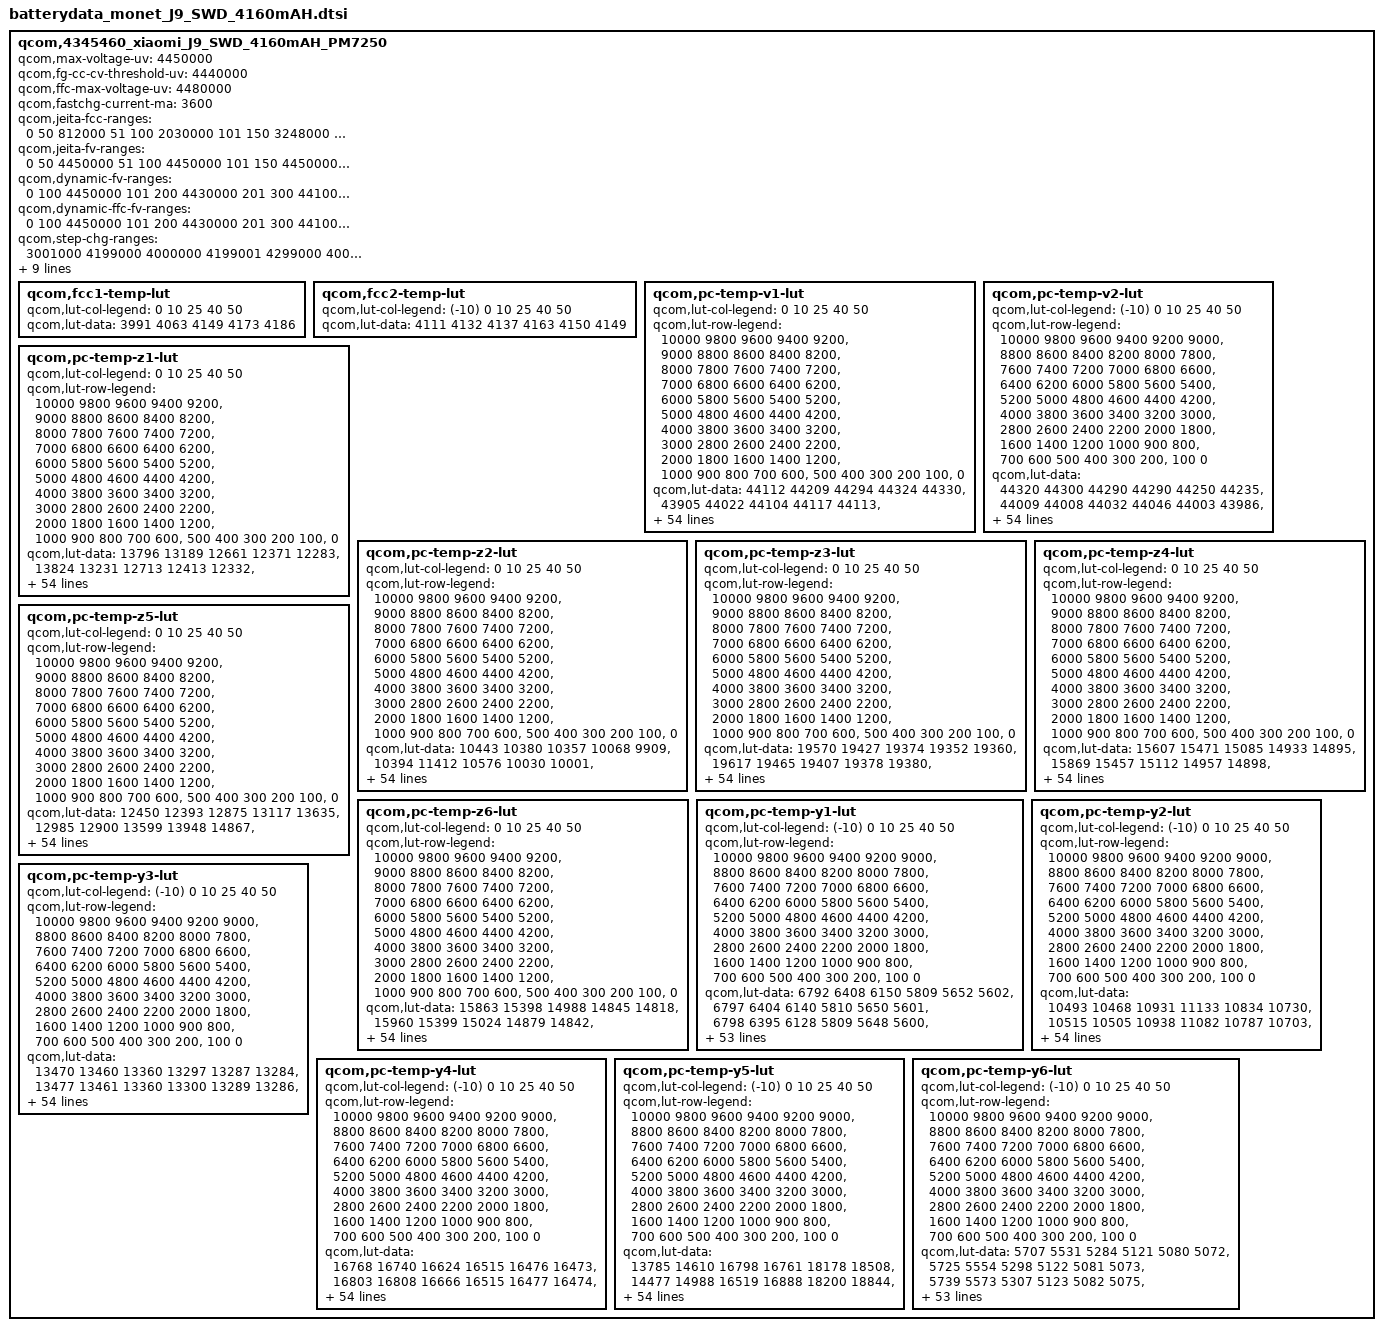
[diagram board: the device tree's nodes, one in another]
qcom,4345460_xiaomi_J9_SWD_4160mAH_PM7250 {
    /* 4345460_xiaomi_J9_SWD_4160mAH_PM7250_averaged_MasterSlave_Dec11th2019 */
    qcom,max-voltage-uv = <4450000>;
    qcom,fg-cc-cv-threshold-uv = <4440000>;
    qcom,ffc-max-voltage-uv = <4480000>;
    qcom,fastchg-current-ma = <3600>;
    qcom,jeita-fcc-ranges = <0  50  812000
			     51  100  2030000
			     101 150  3248000
			     151 450  3600000
			     451 580  2030000>;
    qcom,jeita-fv-ranges = <0   50  4450000
			    51  100  4450000
			    101 150  4450000
			    151 450  4480000
			    451 580  4100000>;
    qcom,dynamic-fv-ranges = <0    100  4450000
			    101  200  4430000
			    201  300  4410000
			    301  400  4390000
			    401  500  4370000>;
    qcom,dynamic-ffc-fv-ranges = <0    100  4450000
			    101  200  4430000
			    201  300  4410000
			    301  400  4390000
			    401  500  4370000>;
    qcom,step-chg-ranges = <3001000  4199000  4000000
			    4199001  4299000  4000000
			    4299001  4399000  4000000
                            4399001  4450000  4000000
                            4450001  4480000  3248000>;
    qcom,fg-cc-cv-threshold-mv = <4440>;
    qcom,nom-batt-capacity-mah = <4160>;
    qcom,batt-id-kohm = <330>;
    qcom,battery-beta = <4250>;
    qcom,battery-therm-kohm = <100>;
    qcom,cutoff-current-ua = <700000>;
    qcom,battery-type = "J9_SWD_4160mAH";
    qcom,qg-batt-profile-ver = <100>;
    mi,qc3p5-ffc-battery;

	qcom,fcc1-temp-lut {
		qcom,lut-col-legend = <0 10 25 40 50>;
		qcom,lut-data = <3991 4063 4149 4173 4186>;
	};

	qcom,fcc2-temp-lut {
		qcom,lut-col-legend = <(-10) 0 10 25 40 50>;
		qcom,lut-data = <4111 4132 4137 4163 4150 4149>;
	};

	qcom,pc-temp-v1-lut {
		qcom,lut-col-legend = <0 10 25 40 50>;
		qcom,lut-row-legend = <10000 9800 9600 9400 9200>,
			<9000 8800 8600 8400 8200>,
			<8000 7800 7600 7400 7200>,
			<7000 6800 6600 6400 6200>,
			<6000 5800 5600 5400 5200>,
			<5000 4800 4600 4400 4200>,
			<4000 3800 3600 3400 3200>,
			<3000 2800 2600 2400 2200>,
			<2000 1800 1600 1400 1200>,
			<1000 900 800 700 600>,
			<500 400 300 200 100>,
			<0>;
		qcom,lut-data = <44112 44209 44294 44324 44330>,
			<43905 44022 44104 44117 44113>,
			<43690 43821 43899 43912 43909>,
			<43468 43605 43692 43705 43704>,
			<43238 43377 43479 43496 43497>,
			<43000 43143 43255 43280 43284>,
			<42761 42903 43017 43049 43057>,
			<42520 42662 42772 42807 42816>,
			<42279 42417 42527 42565 42574>,
			<42042 42174 42281 42323 42333>,
			<41810 41937 42039 42083 42092>,
			<41583 41703 41799 41842 41852>,
			<41361 41475 41563 41602 41614>,
			<41146 41250 41333 41368 41380>,
			<40936 41034 41110 41143 41152>,
			<40733 40830 40895 40925 40929>,
			<40535 40635 40688 40715 40717>,
			<40339 40442 40487 40512 40512>,
			<40147 40256 40298 40318 40317>,
			<39965 40068 40121 40137 40138>,
			<39803 39860 39927 39948 39953>,
			<39635 39629 39675 39712 39723>,
			<39415 39402 39405 39453 39462>,
			<39137 39172 39202 39246 39251>,
			<38926 38970 39040 39081 39088>,
			<38810 38846 38907 38938 38946>,
			<38724 38759 38798 38811 38814>,
			<38651 38680 38702 38698 38694>,
			<38590 38598 38606 38593 38584>,
			<38534 38520 38512 38493 38485>,
			<38476 38448 38426 38404 38395>,
			<38418 38378 38352 38326 38316>,
			<38367 38317 38284 38254 38243>,
			<38320 38264 38223 38187 38172>,
			<38278 38218 38170 38124 38103>,
			<38238 38175 38119 38062 38033>,
			<38202 38139 38070 38003 37966>,
			<38157 38097 38021 37943 37895>,
			<38087 38031 37951 37866 37809>,
			<37994 37935 37854 37765 37700>,
			<37886 37826 37742 37651 37578>,
			<37752 37696 37617 37529 37452>,
			<37599 37548 37474 37393 37315>,
			<37421 37376 37306 37227 37143>,
			<37305 37227 37166 37094 37021>,
			<37212 37137 37085 37021 36958>,
			<37179 37111 37061 36996 36933>,
			<37148 37091 37045 36977 36918>,
			<37114 37073 37015 36952 36884>,
			<37023 36978 36904 36833 36728>,
			<36703 36679 36548 36471 36366>,
			<36214 36208 36065 35997 35891>,
			<35588 35602 35436 35383 35275>,
			<34725 34767 34568 34545 34432>,
			<33326 33440 33177 33221 33097>,
			<30000 30000 30000 30000 30000>;
	};

	qcom,pc-temp-v2-lut {
		qcom,lut-col-legend = <(-10) 0 10 25 40 50>;
		qcom,lut-row-legend = <10000 9800 9600 9400 9200 9000>,
			<8800 8600 8400 8200 8000 7800>,
			<7600 7400 7200 7000 6800 6600>,
			<6400 6200 6000 5800 5600 5400>,
			<5200 5000 4800 4600 4400 4200>,
			<4000 3800 3600 3400 3200 3000>,
			<2800 2600 2400 2200 2000 1800>,
			<1600 1400 1200 1000 900 800>,
			<700 600 500 400 300 200>,
			<100 0>;
		qcom,lut-data = <44320 44300 44290 44290 44250 44235>,
			<44009 44008 44032 44046 44003 43986>,
			<43725 43737 43784 43809 43766 43747>,
			<43471 43492 43551 43583 43538 43519>,
			<43249 43274 43334 43368 43322 43304>,
			<43027 43051 43112 43146 43101 43085>,
			<42788 42808 42872 42909 42866 42851>,
			<42543 42555 42625 42665 42624 42610>,
			<42296 42303 42379 42419 42382 42369>,
			<42046 42052 42131 42173 42138 42125>,
			<41798 41803 41885 41928 41896 41883>,
			<41549 41554 41644 41687 41657 41644>,
			<41302 41309 41406 41449 41422 41409>,
			<41087 41097 41174 41216 41191 41179>,
			<40916 40917 40949 40988 40965 40954>,
			<40726 40734 40733 40767 40747 40736>,
			<40427 40517 40533 40556 40538 40525>,
			<40044 40271 40339 40352 40336 40322>,
			<39753 40022 40130 40156 40144 40130>,
			<39554 39763 39905 39973 39965 39954>,
			<39374 39513 39673 39772 39772 39765>,
			<39179 39278 39432 39514 39528 39523>,
			<38984 39053 39191 39242 39265 39263>,
			<38796 38854 38988 39033 39054 39055>,
			<38606 38678 38816 38862 38879 38883>,
			<38441 38515 38664 38714 38728 38733>,
			<38325 38344 38529 38585 38600 38602>,
			<38233 38181 38408 38471 38488 38486>,
			<38157 38083 38296 38365 38384 38382>,
			<38092 38027 38188 38266 38287 38285>,
			<38033 37983 38090 38176 38199 38197>,
			<37972 37941 38001 38093 38122 38118>,
			<37914 37902 37922 38016 38050 38043>,
			<37855 37860 37861 37944 37975 37963>,
			<37796 37815 37818 37878 37898 37878>,
			<37734 37768 37777 37809 37813 37785>,
			<37669 37714 37735 37734 37712 37677>,
			<37599 37654 37690 37654 37601 37558>,
			<37522 37582 37629 37569 37502 37454>,
			<37434 37493 37543 37482 37416 37365>,
			<37339 37390 37436 37384 37324 37271>,
			<37244 37269 37308 37267 37210 37155>,
			<37150 37132 37161 37140 37085 37029>,
			<37060 36999 37018 37006 36961 36903>,
			<36976 36883 36897 36912 36872 36820>,
			<36891 36795 36820 36867 36836 36783>,
			<36845 36753 36785 36849 36825 36772>,
			<36797 36706 36742 36825 36806 36751>,
			<36740 36630 36669 36765 36754 36687>,
			<36642 36494 36522 36557 36549 36434>,
			<36422 36225 36204 36114 36123 35991>,
			<35991 35754 35711 35534 35567 35428>,
			<35350 35071 35042 34776 34849 34690>,
			<34456 34095 34133 33702 33878 33709>,
			<32973 32497 32635 32152 32265 31950>,
			<29640 27567 28928 26774 27941 27767>;
	};

	qcom,pc-temp-z1-lut {
		qcom,lut-col-legend = <0 10 25 40 50>;
		qcom,lut-row-legend = <10000 9800 9600 9400 9200>,
			<9000 8800 8600 8400 8200>,
			<8000 7800 7600 7400 7200>,
			<7000 6800 6600 6400 6200>,
			<6000 5800 5600 5400 5200>,
			<5000 4800 4600 4400 4200>,
			<4000 3800 3600 3400 3200>,
			<3000 2800 2600 2400 2200>,
			<2000 1800 1600 1400 1200>,
			<1000 900 800 700 600>,
			<500 400 300 200 100>,
			<0>;
		qcom,lut-data = <13796 13189 12661 12371 12283>,
			<13824 13231 12713 12413 12332>,
			<13855 13242 12730 12429 12347>,
			<13873 13242 12729 12433 12353>,
			<13862 13237 12718 12431 12353>,
			<13838 13227 12709 12428 12351>,
			<13822 13210 12702 12424 12349>,
			<13802 13197 12692 12419 12347>,
			<13781 13188 12681 12415 12346>,
			<13770 13178 12670 12411 12346>,
			<13760 13164 12665 12410 12347>,
			<13756 13144 12664 12410 12347>,
			<13748 13134 12664 12410 12348>,
			<13732 13131 12663 12411 12348>,
			<13720 13129 12661 12411 12349>,
			<13699 13126 12661 12411 12350>,
			<13681 13124 12661 12412 12351>,
			<13668 13124 12662 12414 12353>,
			<13656 13125 12663 12416 12355>,
			<13653 13127 12665 12419 12358>,
			<13662 13128 12668 12421 12360>,
			<13673 13131 12670 12421 12361>,
			<13677 13134 12673 12420 12361>,
			<13678 13137 12675 12421 12362>,
			<13678 13140 12678 12424 12364>,
			<13680 13144 12681 12428 12367>,
			<13685 13152 12687 12432 12371>,
			<13686 13158 12693 12436 12375>,
			<13681 13159 12699 12441 12379>,
			<13678 13159 12703 12446 12383>,
			<13683 13162 12707 12451 12387>,
			<13692 13172 12711 12456 12392>,
			<13700 13180 12716 12461 12397>,
			<13709 13186 12722 12467 12402>,
			<13718 13192 12731 12474 12407>,
			<13722 13196 12740 12480 12412>,
			<13726 13197 12746 12485 12417>,
			<13733 13199 12753 12490 12422>,
			<13759 13206 12759 12495 12427>,
			<13794 13222 12765 12500 12431>,
			<13813 13239 12772 12505 12436>,
			<13824 13259 12780 12511 12440>,
			<13829 13275 12790 12516 12443>,
			<13839 13283 12802 12521 12446>,
			<13864 13287 12817 12529 12452>,
			<13892 13296 12828 12535 12454>,
			<13846 13291 12824 12535 12455>,
			<13835 13288 12829 12537 12456>,
			<13864 13297 12836 12542 12461>,
			<13878 13304 12844 12549 12466>,
			<13894 13308 12856 12558 12473>,
			<13890 13322 12864 12563 12482>,
			<13918 13328 12875 12577 12493>,
			<13942 13356 12892 12590 12506>,
			<13942 13356 12892 12590 12506>,
			<13942 13356 12892 12590 12506>;
	};

	qcom,pc-temp-z2-lut {
		qcom,lut-col-legend = <0 10 25 40 50>;
		qcom,lut-row-legend = <10000 9800 9600 9400 9200>,
			<9000 8800 8600 8400 8200>,
			<8000 7800 7600 7400 7200>,
			<7000 6800 6600 6400 6200>,
			<6000 5800 5600 5400 5200>,
			<5000 4800 4600 4400 4200>,
			<4000 3800 3600 3400 3200>,
			<3000 2800 2600 2400 2200>,
			<2000 1800 1600 1400 1200>,
			<1000 900 800 700 600>,
			<500 400 300 200 100>,
			<0>;
		qcom,lut-data = <10443 10380 10357 10068 9909>,
			<10394 11412 10576 10030 10001>,
			<10345 11548 11046 10115 10007>,
			<10304 10931 11145 10154 10005>,
			<10266 10383 10979 10165 9988>,
			<10234 10328 10766 10170 9966>,
			<10214 10301 10543 10161 9974>,
			<10200 10281 10317 10137 10013>,
			<10190 10262 10235 10132 10034>,
			<10187 10250 10202 10370 9991>,
			<10185 10245 10190 10624 9935>,
			<10184 10242 10194 10522 9921>,
			<10191 10242 10203 10200 9917>,
			<10204 10254 10236 10067 9912>,
			<10217 10279 10397 10056 9902>,
			<10230 10392 10539 10052 9897>,
			<10247 10613 10584 10209 9907>,
			<10278 10693 10613 10614 9927>,
			<10317 10543 10594 10734 9942>,
			<10330 10371 10411 10374 9951>,
			<10328 10341 10278 10041 9963>,
			<10325 10341 10332 10120 10049>,
			<10320 10343 10407 10296 10224>,
			<10313 10335 10407 10330 10275>,
			<10309 10322 10339 10197 10178>,
			<10309 10324 10297 10089 10087>,
			<10311 10342 10323 10181 10128>,
			<10315 10362 10369 10364 10231>,
			<10325 10379 10396 10401 10255>,
			<10337 10394 10416 10305 10146>,
			<10346 10395 10424 10201 10019>,
			<10355 10383 10390 10140 9943>,
			<10361 10372 10339 10094 9883>,
			<10364 10370 10330 10085 9872>,
			<10367 10372 10334 10094 9896>,
			<10372 10376 10340 10109 9932>,
			<10380 10382 10358 10148 9979>,
			<10392 10392 10390 10212 10038>,
			<10409 10408 10424 10265 10086>,
			<10431 10434 10469 10314 10134>,
			<10451 10456 10496 10344 10159>,
			<10467 10471 10504 10347 10137>,
			<10499 10489 10510 10344 10108>,
			<10571 10518 10510 10343 10222>,
			<10423 10722 10560 10283 10195>,
			<10307 10787 10558 10208 10088>,
			<10241 10764 10558 10209 10083>,
			<10200 10775 10527 10193 10094>,
			<10172 10868 10553 10245 10167>,
			<10181 10828 10570 10304 10135>,
			<10155 10829 10523 10121 9964>,
			<10027 10692 10398 10025 9906>,
			<9946 10665 10383 9983 9858>,
			<9781 10461 10319 9961 9836>,
			<9781 10461 10319 9961 9836>,
			<9781 10461 10319 9961 9836>;
	};

	qcom,pc-temp-z3-lut {
		qcom,lut-col-legend = <0 10 25 40 50>;
		qcom,lut-row-legend = <10000 9800 9600 9400 9200>,
			<9000 8800 8600 8400 8200>,
			<8000 7800 7600 7400 7200>,
			<7000 6800 6600 6400 6200>,
			<6000 5800 5600 5400 5200>,
			<5000 4800 4600 4400 4200>,
			<4000 3800 3600 3400 3200>,
			<3000 2800 2600 2400 2200>,
			<2000 1800 1600 1400 1200>,
			<1000 900 800 700 600>,
			<500 400 300 200 100>,
			<0>;
		qcom,lut-data = <19570 19427 19374 19352 19360>,
			<19617 19465 19407 19378 19380>,
			<19717 19493 19442 19406 19397>,
			<19779 19559 19468 19426 19409>,
			<19798 19616 19497 19437 19416>,
			<19810 19627 19515 19446 19423>,
			<19816 19633 19517 19453 19431>,
			<19817 19636 19518 19460 19440>,
			<19818 19639 19517 19466 19443>,
			<19819 19641 19515 19477 19442>,
			<19818 19637 19512 19486 19439>,
			<19816 19627 19506 19479 19436>,
			<19809 19619 19499 19459 19432>,
			<19801 19608 19497 19445 19428>,
			<19798 19600 19503 19436 19425>,
			<19797 19607 19507 19430 19421>,
			<19795 19626 19499 19430 19416>,
			<19781 19632 19489 19434 19410>,
			<19758 19606 19479 19433 19404>,
			<19750 19579 19462 19418 19396>,
			<19757 19583 19451 19405 19391>,
			<19769 19609 19467 19410 19394>,
			<19787 19624 19491 19421 19402>,
			<19813 19619 19489 19421 19404>,
			<19827 19607 19460 19397 19390>,
			<19818 19595 19440 19376 19377>,
			<19800 19576 19438 19399 19400>,
			<19785 19566 19437 19446 19454>,
			<19770 19572 19445 19463 19471>,
			<19760 19586 19482 19467 19464>,
			<19759 19598 19505 19469 19453>,
			<19760 19610 19504 19463 19441>,
			<19760 19617 19503 19450 19427>,
			<19757 19614 19500 19439 19415>,
			<19754 19609 19489 19428 19405>,
			<19751 19604 19478 19419 19396>,
			<19748 19599 19471 19411 19389>,
			<19745 19594 19465 19405 19383>,
			<19738 19589 19461 19400 19382>,
			<19729 19582 19458 19397 19381>,
			<19719 19576 19456 19396 19381>,
			<19708 19571 19455 19398 19384>,
			<19691 19564 19454 19402 19392>,
			<19661 19546 19448 19405 19404>,
			<19409 19497 19428 19399 19402>,
			<19338 19473 19409 19371 19372>,
			<19322 19467 19410 19369 19366>,
			<19316 19444 19396 19368 19352>,
			<19312 19335 19393 19351 19345>,
			<19315 19440 19368 19354 19365>,
			<19323 19340 19388 19395 19388>,
			<19324 19321 19380 19396 19389>,
			<19326 19306 19380 19398 19388>,
			<19333 19309 19377 19384 19385>,
			<19333 19309 19377 19384 19385>,
			<19333 19309 19377 19384 19385>;
	};

	qcom,pc-temp-z4-lut {
		qcom,lut-col-legend = <0 10 25 40 50>;
		qcom,lut-row-legend = <10000 9800 9600 9400 9200>,
			<9000 8800 8600 8400 8200>,
			<8000 7800 7600 7400 7200>,
			<7000 6800 6600 6400 6200>,
			<6000 5800 5600 5400 5200>,
			<5000 4800 4600 4400 4200>,
			<4000 3800 3600 3400 3200>,
			<3000 2800 2600 2400 2200>,
			<2000 1800 1600 1400 1200>,
			<1000 900 800 700 600>,
			<500 400 300 200 100>,
			<0>;
		qcom,lut-data = <15607 15471 15085 14933 14895>,
			<15869 15457 15112 14957 14898>,
			<15744 15417 15092 14949 14902>,
			<15595 15323 15060 14938 14904>,
			<15482 15228 15001 14914 14889>,
			<15376 15157 14951 14884 14865>,
			<15286 15094 14924 14860 14844>,
			<15211 15039 14903 14839 14823>,
			<15147 14989 14881 14814 14804>,
			<15091 14948 14857 14773 14787>,
			<15043 14917 14832 14740 14773>,
			<15005 14891 14812 14737 14762>,
			<14974 14868 14793 14746 14752>,
			<14947 14849 14772 14748 14744>,
			<14919 14828 14743 14744 14739>,
			<14887 14791 14724 14739 14734>,
			<14869 14744 14720 14725 14730>,
			<14869 14730 14717 14700 14725>,
			<14871 14754 14715 14690 14720>,
			<14870 14783 14723 14695 14714>,
			<14850 14799 14739 14708 14710>,
			<14828 14814 14775 14740 14731>,
			<14845 14834 14825 14794 14789>,
			<14916 14897 14869 14837 14827>,
			<14964 14962 14917 14877 14850>,
			<14968 14971 14939 14900 14863>,
			<14969 14966 14932 14868 14831>,
			<14966 14958 14916 14800 14756>,
			<14951 14936 14890 14764 14726>,
			<14931 14901 14838 14745 14722>,
			<14912 14872 14799 14733 14718>,
			<14890 14845 14781 14727 14715>,
			<14873 14827 14770 14723 14713>,
			<14860 14820 14766 14722 14711>,
			<14849 14816 14765 14723 14710>,
			<14840 14813 14764 14724 14709>,
			<14833 14811 14765 14725 14710>,
			<14827 14809 14767 14726 14711>,
			<14824 14811 14771 14731 14715>,
			<14822 14814 14781 14747 14731>,
			<14817 14814 14787 14757 14744>,
			<14805 14800 14778 14751 14737>,
			<14792 14783 14765 14741 14726>,
			<14779 14773 14760 14738 14723>,
			<14906 14735 14736 14723 14707>,
			<14949 14714 14710 14713 14694>,
			<14957 14708 14693 14700 14688>,
			<14956 14715 14684 14678 14677>,
			<14956 14829 14670 14670 14654>,
			<14952 14710 14708 14670 14654>,
			<14960 14846 14719 14680 14681>,
			<14973 14875 14733 14685 14687>,
			<14976 14893 14733 14687 14692>,
			<14986 14893 14739 14702 14695>,
			<14986 14893 14739 14702 14695>,
			<14986 14893 14739 14702 14695>;
	};

	qcom,pc-temp-z5-lut {
		qcom,lut-col-legend = <0 10 25 40 50>;
		qcom,lut-row-legend = <10000 9800 9600 9400 9200>,
			<9000 8800 8600 8400 8200>,
			<8000 7800 7600 7400 7200>,
			<7000 6800 6600 6400 6200>,
			<6000 5800 5600 5400 5200>,
			<5000 4800 4600 4400 4200>,
			<4000 3800 3600 3400 3200>,
			<3000 2800 2600 2400 2200>,
			<2000 1800 1600 1400 1200>,
			<1000 900 800 700 600>,
			<500 400 300 200 100>,
			<0>;
		qcom,lut-data = <12450 12393 12875 13117 13635>,
			<12985 12900 13599 13948 14867>,
			<13955 13314 14390 15298 16040>,
			<14657 14357 14938 16273 16865>,
			<14982 15343 15638 16790 17307>,
			<15219 15679 16272 17258 17703>,
			<15499 15944 16650 17849 18431>,
			<15852 16308 16956 18524 19591>,
			<16258 16871 17250 19412 20334>,
			<16755 17397 17538 22023 20623>,
			<17351 17747 17888 24454 20878>,
			<17935 18064 18328 24135 21269>,
			<18468 18463 18904 22354 21975>,
			<19068 18944 19990 21463 22657>,
			<19999 19635 22459 21280 23333>,
			<21620 21784 24337 21192 23907>,
			<22717 25485 24769 22924 24293>,
			<22667 26782 24942 27307 24713>,
			<22422 24457 24746 28838 24823>,
			<22467 21915 22784 26358 25139>,
			<23921 23892 21659 24141 25521>,
			<26611 32120 26045 25165 25881>,
			<31469 36793 32077 26917 26494>,
			<40093 34011 31575 26672 26221>,
			<44573 29025 23907 20505 20783>,
			<40940 25749 18315 15478 15768>,
			<34448 22029 17078 16433 18255>,
			<30508 20195 16390 19008 24598>,
			<27788 20528 16823 21375 27232>,
			<26335 21416 19596 23883 27828>,
			<26665 22836 22531 25579 28089>,
			<27806 25900 24822 25950 27403>,
			<28918 28722 26766 25986 25889>,
			<29957 30392 27699 25969 25244>,
			<30954 31685 28279 26126 25065>,
			<31772 32014 28505 26173 24913>,
			<32539 31914 28342 25879 24732>,
			<33036 31718 27952 25366 24515>,
			<33282 31211 27289 24610 24038>,
			<33408 30199 25840 23239 22660>,
			<33166 29501 24734 22062 21696>,
			<32056 29219 24361 21359 21799>,
			<31028 28707 23999 20966 22166>,
			<29737 26530 22822 21679 25805>,
			<16214 27534 22782 21661 26446>,
			<12816 26290 22098 17822 18932>,
			<12425 24627 23521 18166 18362>,
			<12290 21527 21650 20152 17562>,
			<12198 13348 23410 19300 20562>,
			<12297 20769 16805 18949 30629>,
			<12396 13067 16821 21611 22270>,
			<12228 12417 15367 20154 20120>,
			<12131 11973 15099 19052 18296>,
			<12027 11913 14514 15661 16073>,
			<12027 11913 14514 15661 16073>,
			<12027 11913 14514 15661 16073>;
	};

	qcom,pc-temp-z6-lut {
		qcom,lut-col-legend = <0 10 25 40 50>;
		qcom,lut-row-legend = <10000 9800 9600 9400 9200>,
			<9000 8800 8600 8400 8200>,
			<8000 7800 7600 7400 7200>,
			<7000 6800 6600 6400 6200>,
			<6000 5800 5600 5400 5200>,
			<5000 4800 4600 4400 4200>,
			<4000 3800 3600 3400 3200>,
			<3000 2800 2600 2400 2200>,
			<2000 1800 1600 1400 1200>,
			<1000 900 800 700 600>,
			<500 400 300 200 100>,
			<0>;
		qcom,lut-data = <15863 15398 14988 14845 14818>,
			<15960 15399 15024 14879 14842>,
			<15915 15387 15034 14892 14856>,
			<15854 15360 15030 14895 14860>,
			<15794 15335 15017 14891 14857>,
			<15728 15305 15003 14884 14852>,
			<15671 15266 14991 14878 14848>,
			<15620 15233 14978 14871 14844>,
			<15576 15205 14965 14864 14839>,
			<15539 15181 14952 14855 14832>,
			<15507 15158 14938 14846 14824>,
			<15479 15137 14925 14838 14817>,
			<15454 15118 14913 14831 14811>,
			<15431 15102 14903 14824 14805>,
			<15410 15087 14895 14818 14801>,
			<15391 15075 14888 14812 14796>,
			<15374 15065 14881 14805 14792>,
			<15358 15060 14875 14799 14786>,
			<15345 15057 14870 14794 14781>,
			<15341 15056 14866 14788 14774>,
			<15341 15060 14865 14785 14770>,
			<15341 15081 14887 14800 14781>,
			<15355 15103 14924 14832 14812>,
			<15403 15128 14939 14846 14826>,
			<15431 15150 14946 14851 14829>,
			<15429 15150 14948 14853 14830>,
			<15424 15142 14944 14851 14828>,
			<15416 15133 14937 14848 14826>,
			<15403 15127 14933 14844 14823>,
			<15391 15122 14930 14840 14818>,
			<15383 15118 14927 14835 14812>,
			<15377 15114 14922 14829 14806>,
			<15372 15111 14917 14822 14798>,
			<15367 15108 14913 14817 14791>,
			<15364 15106 14908 14813 14786>,
			<15364 15105 14905 14809 14781>,
			<15365 15104 14903 14805 14778>,
			<15366 15104 14901 14802 14775>,
			<15370 15106 14902 14803 14775>,
			<15376 15110 14907 14808 14782>,
			<15379 15111 14910 14812 14787>,
			<15380 15108 14908 14811 14787>,
			<15380 15104 14904 14810 14786>,
			<15378 15100 14901 14811 14792>,
			<15329 15073 14886 14803 14785>,
			<15310 15056 14868 14785 14764>,
			<15306 15050 14861 14778 14759>,
			<15305 15044 14851 14769 14747>,
			<15310 15040 14845 14756 14733>,
			<15319 15050 14851 14759 14744>,
			<15333 15062 14871 14787 14771>,
			<15347 15070 14876 14793 14778>,
			<15361 15078 14881 14798 14783>,
			<15386 15091 14888 14801 14787>,
			<15386 15091 14888 14801 14787>,
			<15386 15091 14888 14801 14787>;
	};

	qcom,pc-temp-y1-lut {
		qcom,lut-col-legend = <(-10) 0 10 25 40 50>;
		qcom,lut-row-legend = <10000 9800 9600 9400 9200 9000>,
			<8800 8600 8400 8200 8000 7800>,
			<7600 7400 7200 7000 6800 6600>,
			<6400 6200 6000 5800 5600 5400>,
			<5200 5000 4800 4600 4400 4200>,
			<4000 3800 3600 3400 3200 3000>,
			<2800 2600 2400 2200 2000 1800>,
			<1600 1400 1200 1000 900 800>,
			<700 600 500 400 300 200>,
			<100 0>;
		qcom,lut-data = <6792 6408 6150 5809 5652 5602>,
			<6797 6404 6140 5810 5650 5601>,
			<6798 6395 6128 5809 5648 5600>,
			<6798 6385 6117 5808 5646 5599>,
			<6796 6376 6107 5806 5645 5598>,
			<6793 6372 6102 5804 5643 5597>,
			<6786 6372 6100 5799 5641 5596>,
			<6777 6372 6100 5795 5640 5596>,
			<6776 6370 6100 5794 5638 5595>,
			<6785 6363 6095 5795 5637 5593>,
			<6792 6359 6091 5795 5636 5591>,
			<6792 6363 6090 5794 5635 5591>,
			<6792 6372 6089 5792 5634 5591>,
			<6792 6374 6088 5790 5634 5591>,
			<6793 6374 6087 5788 5634 5590>,
			<6796 6374 6086 5788 5634 5590>,
			<6805 6378 6088 5789 5634 5590>,
			<6820 6385 6092 5792 5635 5591>,
			<6826 6388 6092 5792 5636 5592>,
			<6826 6388 6091 5791 5636 5592>,
			<6826 6388 6090 5791 5637 5593>,
			<6828 6387 6090 5793 5638 5594>,
			<6834 6385 6091 5797 5640 5597>,
			<6835 6384 6093 5801 5642 5599>,
			<6817 6385 6100 5806 5645 5601>,
			<6800 6386 6107 5809 5648 5602>,
			<6801 6388 6104 5812 5650 5604>,
			<6810 6392 6099 5813 5652 5606>,
			<6812 6392 6098 5816 5655 5609>,
			<6800 6387 6102 5821 5659 5612>,
			<6785 6383 6107 5826 5662 5615>,
			<6781 6384 6114 5830 5666 5617>,
			<6779 6387 6120 5834 5669 5620>,
			<6776 6386 6122 5837 5673 5622>,
			<6767 6380 6120 5840 5675 5625>,
			<6756 6373 6117 5842 5678 5627>,
			<6753 6368 6116 5846 5681 5629>,
			<6758 6362 6114 5850 5684 5631>,
			<6760 6359 6114 5856 5685 5633>,
			<6749 6356 6113 5863 5686 5635>,
			<6734 6352 6113 5867 5687 5636>,
			<6733 6351 6118 5864 5688 5639>,
			<6743 6352 6126 5863 5690 5642>,
			<6747 6352 6129 5874 5694 5646>,
			<6735 6359 6132 5884 5700 5649>,
			<6761 6373 6148 5890 5704 5649>,
			<6828 6394 6145 5893 5704 5650>,
			<6837 6401 6142 5890 5703 5651>,
			<6838 6401 6141 5892 5704 5652>,
			<6827 6397 6154 5895 5704 5652>,
			<6857 6405 6147 5896 5709 5656>,
			<6942 6435 6149 5905 5713 5660>,
			<7017 6463 6166 5922 5721 5664>,
			<7168 6521 6182 5947 5731 5675>,
			<7168 6521 6182 5947 5731 5675>,
			<7168 6521 6182 5947 5731 5675>;
	};

	qcom,pc-temp-y2-lut {
		qcom,lut-col-legend = <(-10) 0 10 25 40 50>;
		qcom,lut-row-legend = <10000 9800 9600 9400 9200 9000>,
			<8800 8600 8400 8200 8000 7800>,
			<7600 7400 7200 7000 6800 6600>,
			<6400 6200 6000 5800 5600 5400>,
			<5200 5000 4800 4600 4400 4200>,
			<4000 3800 3600 3400 3200 3000>,
			<2800 2600 2400 2200 2000 1800>,
			<1600 1400 1200 1000 900 800>,
			<700 600 500 400 300 200>,
			<100 0>;
		qcom,lut-data = <10493 10468 10931 11133 10834 10730>,
			<10515 10505 10938 11082 10787 10703>,
			<10559 10565 10940 11030 10733 10676>,
			<10610 10630 10939 10982 10681 10648>,
			<10653 10683 10936 10940 10639 10620>,
			<10674 10705 10930 10909 10615 10592>,
			<10676 10702 10917 10886 10610 10559>,
			<10676 10696 10899 10868 10608 10529>,
			<10673 10691 10890 10855 10598 10518>,
			<10650 10680 10882 10843 10568 10513>,
			<10632 10676 10878 10838 10549 10509>,
			<10693 10738 10885 10844 10559 10505>,
			<10818 10845 10905 10860 10581 10500>,
			<10857 10864 10931 10880 10604 10500>,
			<10851 10794 10983 10909 10637 10507>,
			<10846 10737 11032 10944 10673 10512>,
			<10856 10816 11061 10986 10707 10510>,
			<10882 10969 11086 11036 10746 10507>,
			<10911 11025 11117 11102 10811 10536>,
			<10951 11040 11162 11194 10932 10700>,
			<10980 11050 11191 11240 11006 10815>,
			<10979 11078 11188 11201 10989 10800>,
			<10965 11114 11181 11145 10952 10773>,
			<10946 11115 11183 11139 10914 10763>,
			<10910 11030 11196 11155 10864 10760>,
			<10847 10936 11215 11176 10835 10760>,
			<10600 10903 11244 11197 10864 10781>,
			<10057 10881 11280 11221 10925 10825>,
			<9789 10811 11289 11250 10975 10864>,
			<9752 10445 11273 11294 11044 10900>,
			<9730 10061 11249 11330 11109 10945>,
			<9716 9928 11225 11361 11171 11026>,
			<9706 9846 11194 11387 11233 11120>,
			<9698 9785 11163 11385 11247 11162>,
			<9689 9733 11129 11372 11246 11185>,
			<9682 9699 11090 11354 11243 11195>,
			<9678 9685 11042 11316 11169 11101>,
			<9674 9676 10982 11260 11025 10920>,
			<9671 9671 10914 11218 10958 10845>,
			<9670 9668 10841 11185 10931 10823>,
			<9668 9666 10738 11151 10922 10803>,
			<9666 9664 10445 11113 10918 10775>,
			<9665 9662 10017 11067 10888 10735>,
			<9663 9661 9882 10989 10804 10666>,
			<9661 9659 9802 10903 10696 10580>,
			<9658 9658 9777 10890 10698 10550>,
			<9657 9657 9752 10883 10730 10574>,
			<9656 9656 9720 10882 10759 10625>,
			<9654 9656 9706 10884 10782 10629>,
			<9651 9654 9691 10877 10745 10569>,
			<9649 9653 9676 10824 10651 10518>,
			<9648 9652 9663 10733 10556 10470>,
			<9647 9649 9657 10639 10561 10393>,
			<9647 9648 9653 10527 10509 10295>,
			<9647 9648 9653 10527 10509 10295>,
			<9647 9648 9653 10527 10509 10295>;
	};

	qcom,pc-temp-y3-lut {
		qcom,lut-col-legend = <(-10) 0 10 25 40 50>;
		qcom,lut-row-legend = <10000 9800 9600 9400 9200 9000>,
			<8800 8600 8400 8200 8000 7800>,
			<7600 7400 7200 7000 6800 6600>,
			<6400 6200 6000 5800 5600 5400>,
			<5200 5000 4800 4600 4400 4200>,
			<4000 3800 3600 3400 3200 3000>,
			<2800 2600 2400 2200 2000 1800>,
			<1600 1400 1200 1000 900 800>,
			<700 600 500 400 300 200>,
			<100 0>;
		qcom,lut-data = <13470 13460 13360 13297 13287 13284>,
			<13477 13461 13360 13300 13289 13286>,
			<13485 13462 13362 13303 13290 13287>,
			<13493 13463 13363 13305 13292 13289>,
			<13500 13464 13365 13307 13293 13290>,
			<13504 13464 13367 13309 13295 13291>,
			<13506 13465 13368 13310 13296 13292>,
			<13508 13465 13370 13312 13296 13293>,
			<13508 13465 13372 13313 13298 13294>,
			<13502 13464 13373 13315 13299 13295>,
			<13497 13463 13374 13316 13301 13296>,
			<13499 13466 13373 13318 13302 13297>,
			<13505 13471 13371 13319 13303 13298>,
			<13503 13465 13368 13319 13304 13299>,
			<13482 13432 13360 13318 13305 13300>,
			<13464 13411 13355 13318 13306 13301>,
			<13458 13418 13355 13317 13308 13301>,
			<13450 13431 13357 13317 13311 13302>,
			<13444 13432 13357 13317 13311 13302>,
			<13440 13420 13356 13317 13310 13303>,
			<13436 13405 13354 13318 13307 13304>,
			<13429 13394 13349 13313 13302 13299>,
			<13420 13384 13343 13306 13295 13291>,
			<13408 13376 13338 13303 13292 13289>,
			<13389 13371 13336 13301 13291 13289>,
			<13372 13364 13334 13300 13290 13289>,
			<13367 13353 13331 13299 13290 13288>,
			<13367 13338 13329 13299 13290 13288>,
			<13370 13334 13328 13299 13289 13288>,
			<13382 13336 13326 13299 13287 13288>,
			<13398 13341 13325 13299 13286 13288>,
			<13414 13351 13324 13299 13287 13288>,
			<13432 13368 13324 13298 13289 13288>,
			<13453 13388 13324 13298 13290 13288>,
			<13477 13414 13326 13299 13290 13289>,
			<13505 13444 13328 13299 13290 13289>,
			<13536 13480 13332 13299 13289 13289>,
			<13572 13523 13335 13299 13287 13287>,
			<13609 13570 13338 13300 13287 13287>,
			<13647 13620 13341 13300 13290 13289>,
			<13687 13673 13343 13301 13292 13291>,
			<13730 13729 13345 13303 13293 13291>,
			<13780 13790 13349 13304 13292 13290>,
			<13852 13857 13360 13305 13290 13289>,
			<13961 13944 13384 13309 13291 13292>,
			<14114 14022 13407 13313 13301 13296>,
			<14181 14072 13411 13318 13305 13299>,
			<14339 14161 13443 13325 13307 13301>,
			<14619 14267 13476 13330 13307 13300>,
			<15253 14395 13524 13327 13302 13296>,
			<16740 14598 13584 13324 13299 13296>,
			<19896 15172 13730 13330 13302 13299>,
			<27990 16935 14077 13341 13312 13305>,
			<52048 22153 14751 13366 13322 13318>,
			<52048 22153 14751 13366 13322 13318>,
			<52048 22153 14751 13366 13322 13318>;
	};

	qcom,pc-temp-y4-lut {
		qcom,lut-col-legend = <(-10) 0 10 25 40 50>;
		qcom,lut-row-legend = <10000 9800 9600 9400 9200 9000>,
			<8800 8600 8400 8200 8000 7800>,
			<7600 7400 7200 7000 6800 6600>,
			<6400 6200 6000 5800 5600 5400>,
			<5200 5000 4800 4600 4400 4200>,
			<4000 3800 3600 3400 3200 3000>,
			<2800 2600 2400 2200 2000 1800>,
			<1600 1400 1200 1000 900 800>,
			<700 600 500 400 300 200>,
			<100 0>;
		qcom,lut-data = <16768 16740 16624 16515 16476 16473>,
			<16803 16808 16666 16515 16477 16474>,
			<16862 16896 16705 16515 16479 16476>,
			<16928 16983 16738 16516 16480 16478>,
			<16982 17052 16761 16516 16481 16479>,
			<17006 17080 16770 16517 16481 16480>,
			<17003 17072 16763 16517 16482 16480>,
			<16997 17055 16750 16518 16483 16480>,
			<16998 17044 16741 16520 16484 16480>,
			<17011 17038 16734 16523 16485 16481>,
			<17023 17030 16730 16527 16487 16482>,
			<17015 17016 16733 16532 16490 16483>,
			<16998 17000 16741 16538 16494 16486>,
			<17007 17014 16754 16546 16499 16488>,
			<17096 17130 16785 16558 16504 16492>,
			<17171 17218 16814 16573 16509 16496>,
			<17095 17180 16833 16592 16516 16503>,
			<16915 17090 16849 16615 16524 16511>,
			<16837 17017 16848 16637 16539 16525>,
			<16824 16960 16819 16661 16573 16548>,
			<16812 16906 16778 16672 16594 16562>,
			<16788 16854 16729 16628 16572 16547>,
			<16753 16803 16672 16559 16531 16518>,
			<16727 16758 16639 16531 16506 16499>,
			<16706 16716 16618 16516 16490 16483>,
			<16693 16678 16604 16510 16482 16476>,
			<16704 16639 16597 16514 16484 16477>,
			<16738 16604 16592 16520 16490 16481>,
			<16758 16598 16585 16525 16498 16486>,
			<16763 16619 16574 16531 16511 16494>,
			<16767 16646 16562 16536 16522 16502>,
			<16773 16664 16553 16544 16532 16514>,
			<16779 16679 16543 16551 16541 16527>,
			<16785 16697 16543 16552 16542 16529>,
			<16794 16719 16555 16551 16541 16529>,
			<16803 16739 16575 16549 16538 16528>,
			<16807 16757 16597 16537 16522 16517>,
			<16810 16773 16622 16523 16498 16498>,
			<16811 16778 16639 16519 16492 16493>,
			<16804 16778 16647 16518 16493 16497>,
			<16795 16777 16655 16518 16494 16500>,
			<16794 16769 16669 16520 16491 16496>,
			<16794 16750 16682 16522 16484 16486>,
			<16801 16739 16681 16521 16476 16468>,
			<16825 16736 16679 16525 16477 16468>,
			<16849 16738 16681 16527 16502 16517>,
			<16829 16739 16685 16546 16532 16552>,
			<16839 16762 16720 16577 16568 16587>,
			<16860 16794 16765 16609 16592 16598>,
			<16918 16827 16805 16586 16544 16527>,
			<17124 16831 16816 16541 16494 16491>,
			<17601 16851 16837 16554 16496 16492>,
			<19309 17248 16870 16585 16503 16498>,
			<27643 19748 16998 16660 16557 16562>,
			<27643 19748 16998 16660 16557 16562>,
			<27643 19748 16998 16660 16557 16562>;
	};

	qcom,pc-temp-y5-lut {
		qcom,lut-col-legend = <(-10) 0 10 25 40 50>;
		qcom,lut-row-legend = <10000 9800 9600 9400 9200 9000>,
			<8800 8600 8400 8200 8000 7800>,
			<7600 7400 7200 7000 6800 6600>,
			<6400 6200 6000 5800 5600 5400>,
			<5200 5000 4800 4600 4400 4200>,
			<4000 3800 3600 3400 3200 3000>,
			<2800 2600 2400 2200 2000 1800>,
			<1600 1400 1200 1000 900 800>,
			<700 600 500 400 300 200>,
			<100 0>;
		qcom,lut-data = <13785 14610 16798 16761 18178 18508>,
			<14477 14988 16519 16888 18200 18844>,
			<15189 15368 16325 16921 18142 19026>,
			<15864 15725 16203 16878 18021 19085>,
			<16447 16032 16139 16779 17853 19048>,
			<16881 16263 16118 16643 17653 18945>,
			<17218 16443 16180 16403 17382 18742>,
			<17474 16577 16287 16077 17077 18443>,
			<17473 16599 16286 15792 16862 18125>,
			<17059 16509 16162 15528 16715 17751>,
			<16620 16362 15971 15267 16548 17416>,
			<16800 16437 15654 15020 16299 17134>,
			<17362 16643 15179 14763 15994 16833>,
			<17523 16512 14634 14412 15659 16525>,
			<18222 15818 13888 13918 15236 16207>,
			<18960 15636 13449 13585 15009 15849>,
			<18809 17226 14041 13448 15047 15294>,
			<18305 19533 15468 13394 15118 14738>,
			<18296 20353 16952 13771 15142 14652>,
			<19476 20632 18743 15454 15129 14842>,
			<20564 20834 20026 17094 15131 15157>,
			<20564 21169 20508 18291 16309 15938>,
			<20308 21649 20840 19202 18268 17149>,
			<19809 22028 21085 19230 18670 18062>,
			<17456 22952 21282 18664 18395 18921>,
			<14686 23745 21462 18160 18000 19355>,
			<13427 21334 21640 17834 17344 18339>,
			<12554 15822 21820 17575 16419 16580>,
			<12303 13552 22065 17569 15676 15918>,
			<12385 13131 22587 17813 14985 15566>,
			<12515 12950 22989 18007 14626 15407>,
			<12637 13116 22540 18109 15126 15533>,
			<12801 13456 21077 18275 16240 15806>,
			<12974 13602 19975 18646 17247 16330>,
			<13164 13717 18875 19716 18374 17621>,
			<13368 13847 18010 20379 19024 18806>,
			<13576 13975 17600 20152 18907 19546>,
			<13800 14115 17252 19651 18651 20236>,
			<13889 14158 16876 19063 18622 20664>,
			<13819 14088 16523 18096 19245 21185>,
			<13664 14001 16099 17456 19799 21842>,
			<13450 14002 15191 17250 20341 23040>,
			<13133 14028 14120 17018 20603 24007>,
			<12898 13933 14016 16345 17738 20490>,
			<12724 13773 14014 16167 15816 17565>,
			<12768 13542 14004 16417 16645 15557>,
			<12881 13472 13915 16669 16711 15345>,
			<12951 13564 14045 17287 16463 15215>,
			<13118 13822 14170 17903 16226 15181>,
			<12984 14162 14484 18469 16099 15398>,
			<11806 14189 14172 18995 16934 16275>,
			<10408 13368 13768 18858 16742 16261>,
			<9511 11338 13550 19085 20234 17557>,
			<9039 9642 12887 21048 24489 24314>,
			<9039 9642 12887 21048 24489 24314>,
			<9039 9642 12887 21048 24489 24314>;
	};

	qcom,pc-temp-y6-lut {
		qcom,lut-col-legend = <(-10) 0 10 25 40 50>;
		qcom,lut-row-legend = <10000 9800 9600 9400 9200 9000>,
			<8800 8600 8400 8200 8000 7800>,
			<7600 7400 7200 7000 6800 6600>,
			<6400 6200 6000 5800 5600 5400>,
			<5200 5000 4800 4600 4400 4200>,
			<4000 3800 3600 3400 3200 3000>,
			<2800 2600 2400 2200 2000 1800>,
			<1600 1400 1200 1000 900 800>,
			<700 600 500 400 300 200>,
			<100 0>;
		qcom,lut-data = <5707 5531 5284 5121 5080 5072>,
			<5725 5554 5298 5122 5081 5073>,
			<5739 5573 5307 5123 5082 5075>,
			<5750 5588 5312 5124 5084 5077>,
			<5757 5597 5315 5125 5085 5078>,
			<5759 5600 5315 5126 5086 5079>,
			<5756 5596 5313 5126 5087 5080>,
			<5749 5588 5307 5127 5088 5081>,
			<5747 5582 5303 5128 5089 5082>,
			<5746 5577 5300 5130 5091 5082>,
			<5745 5573 5298 5132 5092 5083>,
			<5744 5569 5297 5134 5094 5085>,
			<5743 5566 5296 5136 5095 5086>,
			<5745 5568 5296 5139 5097 5087>,
			<5762 5582 5299 5142 5099 5089>,
			<5776 5593 5302 5145 5102 5091>,
			<5755 5589 5308 5150 5105 5093>,
			<5705 5577 5314 5156 5109 5096>,
			<5688 5564 5314 5162 5114 5100>,
			<5688 5542 5305 5169 5122 5107>,
			<5689 5521 5293 5173 5126 5112>,
			<5686 5506 5276 5158 5117 5104>,
			<5679 5492 5256 5133 5099 5088>,
			<5673 5483 5246 5123 5090 5081>,
			<5667 5477 5239 5118 5084 5077>,
			<5663 5472 5236 5116 5082 5075>,
			<5667 5466 5235 5117 5082 5075>,
			<5683 5462 5235 5119 5084 5076>,
			<5702 5462 5235 5121 5086 5077>,
			<5722 5483 5234 5123 5089 5080>,
			<5745 5514 5234 5126 5092 5083>,
			<5771 5545 5234 5129 5096 5086>,
			<5798 5581 5236 5131 5100 5090>,
			<5829 5621 5240 5133 5101 5091>,
			<5862 5668 5251 5134 5101 5092>,
			<5898 5719 5267 5134 5100 5092>,
			<5936 5774 5285 5132 5096 5089>,
			<5975 5834 5307 5129 5088 5083>,
			<6014 5892 5331 5128 5086 5082>,
			<6052 5949 5355 5130 5089 5085>,
			<6090 6006 5381 5131 5091 5087>,
			<6134 6062 5409 5134 5090 5085>,
			<6185 6120 5440 5138 5089 5082>,
			<6261 6185 5477 5142 5087 5078>,
			<6377 6270 5530 5150 5088 5080>,
			<6547 6353 5572 5154 5103 5098>,
			<6623 6404 5588 5164 5114 5111>,
			<6778 6489 5643 5178 5126 5122>,
			<7043 6595 5705 5190 5133 5125>,
			<7625 6721 5779 5182 5116 5101>,
			<8913 6907 5867 5170 5100 5092>,
			<11442 7406 6043 5185 5103 5095>,
			<17725 8939 6398 5212 5114 5103>,
			<36138 13501 7031 5267 5140 5133>,
			<36138 13501 7031 5267 5140 5133>,
			<36138 13501 7031 5267 5140 5133>;
	};

};
